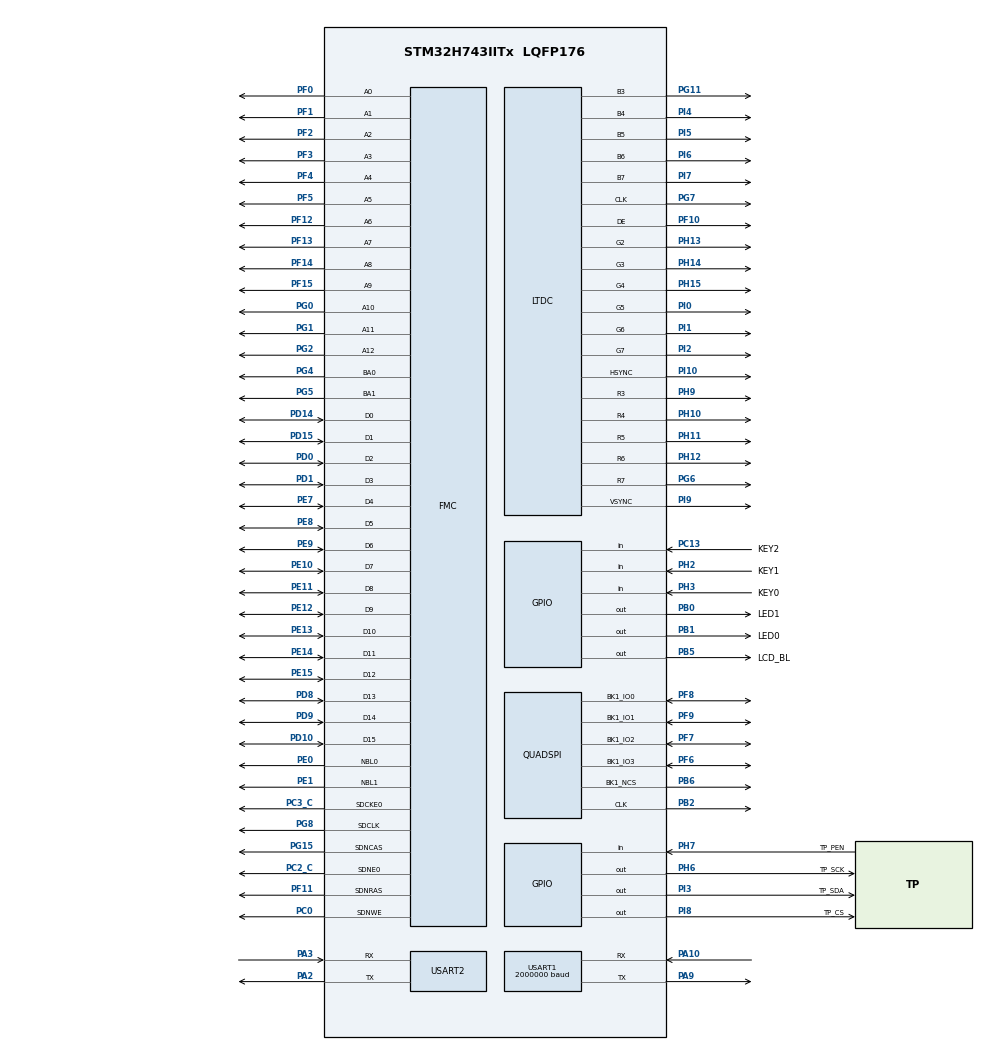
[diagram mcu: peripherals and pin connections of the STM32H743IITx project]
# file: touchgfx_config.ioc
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DMA2D.ColorMode=DMA2D_OUTPUT_RGB565
FMC.CASLatency1=FMC_SDRAM_CAS_LATENCY_3
FMC.ColumnBitsNumber1=FMC_SDRAM_COLUMN_BITS_NUM_9
FMC.ExitSelfRefreshDelay1=8
FMC.LoadToActiveDelay1=2
FMC.RCDDelay1=2
FMC.RPDelay1=2
FMC.RPDelay2=2
FMC.ReadBurst1=FMC_SDRAM_RBURST_ENABLE
FMC.ReadBurst2=FMC_SDRAM_RBURST_ENABLE
FMC.ReadPipeDelay1=FMC_SDRAM_RPIPE_DELAY_1
FMC.ReadPipeDelay2=FMC_SDRAM_RPIPE_DELAY_1
FMC.RowCycleDelay1=6
FMC.RowCycleDelay2=6
FMC.SDClockPeriod1=FMC_SDRAM_CLOCK_PERIOD_2
FMC.SDClockPeriod2=FMC_SDRAM_CLOCK_PERIOD_2
FMC.SelfRefreshTime1=6
FMC.WriteRecoveryTime1=6
FREERTOS.Tasks01=defaultTask,0,128,StartDefaultTask,Default,NULL,Dynamic,NULL,NULL;touchgfx,-2,4096,touchgfx_task,Default,NULL,Dynamic,NULL,NULL
FREERTOS.configTOTAL_HEAP_SIZE=32768
FREERTOS.configUSE_NEWLIB_REENTRANT=1
LTDC.ActiveH=600
LTDC.ActiveW=1024
LTDC.Alpha_L0=255
LTDC.FBStartAdress_L0=0xC0000000
LTDC.HBP=140
LTDC.HFP=160
LTDC.HSync=20
LTDC.ImageHeight_L0=600
LTDC.ImageWidth_L0=1024
LTDC.Layers=0
LTDC.PixelFormat_L0=LTDC_PIXEL_FORMAT_RGB565
LTDC.VBP=20
LTDC.VFP=12
LTDC.VSync=3
LTDC.WindowX1_L0=1024
LTDC.WindowY1_L0=600
Mcu.Family=STM32H7
Mcu.Name=STM32H743IITx
Mcu.Package=LQFP176
NVIC.DMA2D_IRQn=true\:5\:0\:false\:false\:true\:true\:true\:true\:true
NVIC.LTDC_IRQn=true\:8\:0\:true\:false\:true\:true\:true\:true\:true
NVIC.PriorityGroup=NVIC_PRIORITYGROUP_4
NVIC.TIM3_IRQn=true\:7\:0\:true\:false\:true\:true\:true\:true\:true
NVIC.TIM7_IRQn=true\:15\:0\:false\:false\:true\:false\:false\:true\:true
NVIC.TimeBase=TIM7_IRQn
NVIC.TimeBaseIP=TIM7
NVIC.USART1_IRQn=true\:6\:0\:true\:false\:true\:true\:true\:true\:true
NVIC.USART2_IRQn=true\:5\:0\:false\:false\:true\:true\:true\:true\:true
PA10.Mode=Asynchronous
PA10.Signal=USART1_RX
PA13\ (JTMS/SWDIO).Mode=Serial_Wire
PA13\ (JTMS/SWDIO).Signal=DEBUG_JTMS-SWDIO
PA14\ (JTCK/SWCLK).Mode=Serial_Wire
PA14\ (JTCK/SWCLK).Signal=DEBUG_JTCK-SWCLK
PA2.Mode=Asynchronous
PA2.Signal=USART2_TX
PA3.Mode=Asynchronous
PA3.Signal=USART2_RX
PA9.Mode=Asynchronous
PA9.Signal=USART1_TX
PB0.GPIO_Label=LED1
PB0.GPIO_PuPd=GPIO_PULLUP
PB0.GPIO_Speed=GPIO_SPEED_FREQ_HIGH
PB0.PinState=GPIO_PIN_SET
PB0.Signal=GPIO_Output
PB1.GPIO_Label=LED0
PB1.GPIO_PuPd=GPIO_PULLUP
PB1.GPIO_Speed=GPIO_SPEED_FREQ_HIGH
PB1.PinState=GPIO_PIN_SET
PB1.Signal=GPIO_Output
PB2.GPIO_Speed=GPIO_SPEED_FREQ_VERY_HIGH
PB2.Mode=Single Bank 1
PB2.Signal=QUADSPI_CLK
PB5.GPIO_Label=LCD_BL
PB5.PinState=GPIO_PIN_SET
PB5.Signal=GPIO_Output
PB6.GPIO_PuPd=GPIO_PULLUP
PB6.GPIO_Speed=GPIO_SPEED_FREQ_VERY_HIGH
PB6.Mode=Single Bank 1
PB6.Signal=QUADSPI_BK1_NCS
PC0.Signal=FMC_SDNWE
PC13.GPIO_Label=KEY2
PC13.GPIO_PuPd=GPIO_PULLUP
PC13.Signal=GPIO_Input
PC14-OSC32_IN\ (OSC32_IN).Mode=LSE-External-Oscillator
PC14-OSC32_IN\ (OSC32_IN).Signal=RCC_OSC32_IN
PC15-OSC32_OUT\ (OSC32_OUT).Mode=LSE-External-Oscillator
PC15-OSC32_OUT\ (OSC32_OUT).Signal=RCC_OSC32_OUT
PC2_C.Mode=SdramChipSelect1_1
PC2_C.Signal=FMC_SDNE0
PC3_C.Mode=SdramChipSelect1_1
PC3_C.Signal=FMC_SDCKE0
PD0.Signal=FMC_D2_DA2
PD1.Signal=FMC_D3_DA3
PD10.Signal=FMC_D15_DA15
PD14.Signal=FMC_D0_DA0
PD15.Signal=FMC_D1_DA1
PD8.Signal=FMC_D13_DA13
PD9.Signal=FMC_D14_DA14
PE0.Signal=FMC_NBL0
PE1.Signal=FMC_NBL1
PE10.Signal=FMC_D7_DA7
PE11.Signal=FMC_D8_DA8
PE12.Signal=FMC_D9_DA9
PE13.Signal=FMC_D10_DA10
PE14.Signal=FMC_D11_DA11
PE15.Signal=FMC_D12_DA12
PE7.Signal=FMC_D4_DA4
PE8.Signal=FMC_D5_DA5
PE9.Signal=FMC_D6_DA6
PF0.Signal=FMC_A0
PF1.Signal=FMC_A1
PF10.GPIO_Speed=GPIO_SPEED_FREQ_VERY_HIGH
PF10.Mode=RGB565
PF10.Signal=LTDC_DE
PF11.Signal=FMC_SDNRAS
PF12.Signal=FMC_A6
PF13.Signal=FMC_A7
PF14.Signal=FMC_A8
PF15.Signal=FMC_A9
PF2.Signal=FMC_A2
PF3.Signal=FMC_A3
PF4.Signal=FMC_A4
PF5.Signal=FMC_A5
PF6.GPIO_Speed=GPIO_SPEED_FREQ_VERY_HIGH
PF6.Mode=Single Bank 1
PF6.Signal=QUADSPI_BK1_IO3
PF7.GPIO_Speed=GPIO_SPEED_FREQ_VERY_HIGH
PF7.Mode=Single Bank 1
PF7.Signal=QUADSPI_BK1_IO2
PF8.GPIO_Speed=GPIO_SPEED_FREQ_VERY_HIGH
PF8.Mode=Single Bank 1
PF8.Signal=QUADSPI_BK1_IO0
PF9.GPIO_Speed=GPIO_SPEED_FREQ_VERY_HIGH
PF9.Mode=Single Bank 1
PF9.Signal=QUADSPI_BK1_IO1
PG0.Signal=FMC_A10
PG1.Signal=FMC_A11
PG11.GPIO_Speed=GPIO_SPEED_FREQ_VERY_HIGH
PG11.Mode=RGB565
PG11.Signal=LTDC_B3
PG15.Signal=FMC_SDNCAS
PG2.Signal=FMC_A12
PG4.Signal=FMC_A14_BA0
PG5.Signal=FMC_A15_BA1
PG6.GPIO_Speed=GPIO_SPEED_FREQ_VERY_HIGH
PG6.Mode=RGB565
PG6.Signal=LTDC_R7
PG7.GPIO_Speed=GPIO_SPEED_FREQ_VERY_HIGH
PG7.Mode=RGB565
PG7.Signal=LTDC_CLK
PG8.Signal=FMC_SDCLK
PH0-OSC_IN\ (PH0).Mode=HSE-External-Oscillator
PH0-OSC_IN\ (PH0).Signal=RCC_OSC_IN
PH1-OSC_OUT\ (PH1).Mode=HSE-External-Oscillator
PH1-OSC_OUT\ (PH1).Signal=RCC_OSC_OUT
PH10.GPIO_Speed=GPIO_SPEED_FREQ_VERY_HIGH
PH10.Mode=RGB565
PH10.Signal=LTDC_R4
PH11.GPIO_Speed=GPIO_SPEED_FREQ_VERY_HIGH
PH11.Mode=RGB565
PH11.Signal=LTDC_R5
PH12.GPIO_Speed=GPIO_SPEED_FREQ_VERY_HIGH
PH12.Mode=RGB565
PH12.Signal=LTDC_R6
PH13.GPIO_Speed=GPIO_SPEED_FREQ_VERY_HIGH
PH13.Mode=RGB565
PH13.Signal=LTDC_G2
PH14.GPIO_Speed=GPIO_SPEED_FREQ_VERY_HIGH
PH14.Mode=RGB565
PH14.Signal=LTDC_G3
PH15.GPIO_Speed=GPIO_SPEED_FREQ_VERY_HIGH
PH15.Mode=RGB565
PH15.Signal=LTDC_G4
PH2.GPIO_Label=KEY1
PH2.GPIO_PuPd=GPIO_PULLUP
PH2.Signal=GPIO_Input
PH3.GPIO_Label=KEY0
PH3.GPIO_PuPd=GPIO_PULLUP
PH3.Signal=GPIO_Input
PH6.GPIO_Label=TP_SCK
PH6.GPIO_PuPd=GPIO_PULLUP
PH6.GPIO_Speed=GPIO_SPEED_FREQ_HIGH
PH6.PinState=GPIO_PIN_SET
PH6.Signal=GPIO_Output
PH7.GPIO_Label=TP_PEN
PH7.Signal=GPIO_Input
PH9.GPIO_Speed=GPIO_SPEED_FREQ_VERY_HIGH
PH9.Mode=RGB565
PH9.Signal=LTDC_R3
PI0.GPIO_Speed=GPIO_SPEED_FREQ_VERY_HIGH
PI0.Mode=RGB565
PI0.Signal=LTDC_G5
PI1.GPIO_Speed=GPIO_SPEED_FREQ_VERY_HIGH
PI1.Mode=RGB565
PI1.Signal=LTDC_G6
PI10.GPIO_Speed=GPIO_SPEED_FREQ_VERY_HIGH
PI10.Mode=RGB565
PI10.Signal=LTDC_HSYNC
PI2.GPIO_Speed=GPIO_SPEED_FREQ_VERY_HIGH
PI2.Mode=RGB565
PI2.Signal=LTDC_G7
PI3.GPIO_Label=TP_SDA
PI3.GPIO_ModeDefaultOutputPP=GPIO_MODE_OUTPUT_OD
PI3.GPIO_PuPd=GPIO_PULLUP
PI3.PinState=GPIO_PIN_SET
PI3.Signal=GPIO_Output
PI4.GPIO_Speed=GPIO_SPEED_FREQ_VERY_HIGH
PI4.Mode=RGB565
PI4.Signal=LTDC_B4
PI5.GPIO_Speed=GPIO_SPEED_FREQ_VERY_HIGH
PI5.Mode=RGB565
PI5.Signal=LTDC_B5
PI6.GPIO_Speed=GPIO_SPEED_FREQ_VERY_HIGH
PI6.Mode=RGB565
PI6.Signal=LTDC_B6
PI7.GPIO_Speed=GPIO_SPEED_FREQ_VERY_HIGH
PI7.Mode=RGB565
PI7.Signal=LTDC_B7
PI8.GPIO_Label=TP_CS
PI8.GPIO_PuPd=GPIO_PULLUP
PI8.GPIO_Speed=GPIO_SPEED_FREQ_LOW
PI8.PinState=GPIO_PIN_SET
PI8.Signal=GPIO_Output
PI9.GPIO_Speed=GPIO_SPEED_FREQ_VERY_HIGH
PI9.Mode=RGB565
PI9.Signal=LTDC_VSYNC
ProjectManager.HeapSize=0x200
ProjectManager.StackSize=0x400
ProjectManager.TargetToolchain=STM32CubeIDE
QUADSPI.ChipSelectHighTime=QSPI_CS_HIGH_TIME_5_CYCLE
QUADSPI.ClockMode=QSPI_CLOCK_MODE_0
QUADSPI.ClockPrescaler=1
QUADSPI.FifoThreshold=4
QUADSPI.FlashSize=24
QUADSPI.SampleShifting=QSPI_SAMPLE_SHIFTING_HALFCYCLE
RCC.ADCFreq_Value=50390625
RCC.APB1Freq_Value=100000000
RCC.APB2Freq_Value=100000000
RCC.APB3Freq_Value=100000000
RCC.APB4Freq_Value=100000000
RCC.CortexFreq_Value=400000000
RCC.D1PPRE=RCC_APB3_DIV2
RCC.D2PPRE1=RCC_APB1_DIV2
RCC.D2PPRE2=RCC_APB2_DIV2
RCC.D3PPRE=RCC_APB4_DIV2
RCC.DIVM1=2
RCC.DIVN1=64
RCC.DIVN3=192
RCC.DIVR3=3
RCC.HCLKFreq_Value=200000000
RCC.HPRE=RCC_HCLK_DIV2
RCC.PLL2FRACN=0
RCC.PLL3FRACN=0
RCC.PLLFRACN=0
RCC.PLLSourceVirtual=RCC_PLLSOURCE_HSE
RCC.SYSCLKFreq_VALUE=400000000
RCC.SYSCLKSource=RCC_SYSCLKSOURCE_PLLCLK
RCC.USBFreq_Value=400000000
SH.FMC_A0.0=FMC_A0,13b-sda1
SH.FMC_A1.0=FMC_A1,13b-sda1
SH.FMC_A10.0=FMC_A10,13b-sda1
SH.FMC_A11.0=FMC_A11,13b-sda1
SH.FMC_A12.0=FMC_A12,13b-sda1
SH.FMC_A14_BA0.0=FMC_BA0,FourSdramBanks1
SH.FMC_A15_BA1.0=FMC_BA1,FourSdramBanks1
SH.FMC_A2.0=FMC_A2,13b-sda1
SH.FMC_A3.0=FMC_A3,13b-sda1
SH.FMC_A4.0=FMC_A4,13b-sda1
SH.FMC_A5.0=FMC_A5,13b-sda1
SH.FMC_A6.0=FMC_A6,13b-sda1
SH.FMC_A7.0=FMC_A7,13b-sda1
SH.FMC_A8.0=FMC_A8,13b-sda1
SH.FMC_A9.0=FMC_A9,13b-sda1
SH.FMC_D0_DA0.0=FMC_D0,sd-16b-d1
SH.FMC_D10_DA10.0=FMC_D10,sd-16b-d1
SH.FMC_D11_DA11.0=FMC_D11,sd-16b-d1
SH.FMC_D12_DA12.0=FMC_D12,sd-16b-d1
SH.FMC_D13_DA13.0=FMC_D13,sd-16b-d1
SH.FMC_D14_DA14.0=FMC_D14,sd-16b-d1
SH.FMC_D15_DA15.0=FMC_D15,sd-16b-d1
SH.FMC_D1_DA1.0=FMC_D1,sd-16b-d1
SH.FMC_D2_DA2.0=FMC_D2,sd-16b-d1
SH.FMC_D3_DA3.0=FMC_D3,sd-16b-d1
SH.FMC_D4_DA4.0=FMC_D4,sd-16b-d1
SH.FMC_D5_DA5.0=FMC_D5,sd-16b-d1
SH.FMC_D6_DA6.0=FMC_D6,sd-16b-d1
SH.FMC_D7_DA7.0=FMC_D7,sd-16b-d1
SH.FMC_D8_DA8.0=FMC_D8,sd-16b-d1
SH.FMC_D9_DA9.0=FMC_D9,sd-16b-d1
SH.FMC_NBL0.0=FMC_NBL0,Sd2ByteEnable1
SH.FMC_NBL1.0=FMC_NBL1,Sd2ByteEnable1
SH.FMC_SDCLK.0=FMC_SDCLK,13b-sda1
SH.FMC_SDNCAS.0=FMC_SDNCAS,13b-sda1
SH.FMC_SDNRAS.0=FMC_SDNRAS,13b-sda1
SH.FMC_SDNWE.0=FMC_SDNWE,13b-sda1
STMicroelectronics.X-CUBE-TOUCHGFX.4.22.1.ApplicationCcGraphicsJjApplication=TouchGFXOoGenerator
STMicroelectronics.X-CUBE-TOUCHGFX.4.22.1.tgfx_address1=0xC0000000
STMicroelectronics.X-CUBE-TOUCHGFX.4.22.1.tgfx_custom_height=600
STMicroelectronics.X-CUBE-TOUCHGFX.4.22.1.tgfx_display_interface=disp_ltdc
STMicroelectronics.X-CUBE-TOUCHGFX.4.22.1.tgfx_hardware_accelerator=dma_2d
STMicroelectronics.X-CUBE-TOUCHGFX.4.22.1.tgfx_location=By Address
STMicroelectronics.X-CUBE-TOUCHGFX.4.22.1.tgfx_vsync=vsync_ltdc
STMicroelectronics.X-CUBE-TOUCHGFX.4.22.1_IsPackSelfContextualization=true
USART1.BaudRate=2000000
USART1.VirtualMode-Asynchronous=VM_ASYNC
USART2.VirtualMode-Asynchronous=VM_ASYNC
VP_CRC_VS_CRC.Mode=CRC_Activate
VP_DMA2D_VS_DMA2D.Mode=DMA2D_Activate
VP_FREERTOS_VS_CMSIS_V1.Mode=CMSIS_V1
VP_STMicroelectronics.X-CUBE-TOUCHGFX_VS_GraphicsJjApplication_4.22.1.Mode=GraphicsJjApplication
VP_SYS_VS_tim7.Mode=TIM7
VP_TIM3_VS_ClockSourceINT.Mode=Internal
board=custom

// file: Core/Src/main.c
/* USER CODE BEGIN Header */
/**
  ******************************************************************************
  * @file           : main.c
  * @brief          : Main program body
  ******************************************************************************
  * @attention
  *
  * Copyright (c) 2023 STMicroelectronics.
  * All rights reserved.
  *
  * This software is licensed under terms that can be found in the LICENSE file
  * in the root directory of this software component.
  * If no LICENSE file comes with this software, it is provided AS-IS.
  *
  ******************************************************************************
  */
/* USER CODE END Header */
#include "main.h"
#include "cmsis_os.h"
#include "crc.h"
#include "dma2d.h"
#include "ltdc.h"
#include "quadspi.h"
#include "tim.h"
#include "usart.h"
#include "gpio.h"
#include "fmc.h"
#include "app_touchgfx.h"

/* USER CODE BEGIN Includes */
#include "sdram.h"
#include "stdio.h"
#include "user_uart.h"
#include "key_led.h"
#include "user_delay.h"
#include "touch.h"
#include "quadspi.h"

/* USER CODE END Includes */

void SystemClock_Config(void);
void MX_FREERTOS_Init(void);

int main(void)
{

  /* MCU Configuration--------------------------------------------------------*/

  /* Reset of all peripherals, Initializes the Flash interface and the Systick. */
  HAL_Init();

  /* Configure the system clock */
  SystemClock_Config();

  /* Initialize all configured peripherals */
  MX_GPIO_Init();
  MX_TIM3_Init();
  MX_USART1_UART_Init();
  MX_USART2_UART_Init();
  MX_FMC_Init();
  MX_LTDC_Init();
  MX_DMA2D_Init();
  MX_QUADSPI_Init();
  MX_CRC_Init();
  MX_TouchGFX_Init();
  /* Call PreOsInit function */
  MX_TouchGFX_PreOSInit();
  /* USER CODE BEGIN 2 */
  log_com_uart_init();
  SDRAM_Init();
  w25qxx_flash_init();
  /* USER CODE END 2 */

  /* Call init function for freertos objects (in freertos.c) */
  MX_FREERTOS_Init();

  /* Start scheduler */
  osKernelStart();

  /* We should never get here as control is now taken by the scheduler */
  /* Infinite loop */
  while (1)
  {

  }
}

void SystemClock_Config(void)
{
  RCC_OscInitTypeDef RCC_OscInitStruct = {0};
  RCC_ClkInitTypeDef RCC_ClkInitStruct = {0};

  /** Supply configuration update enable
  */
  HAL_PWREx_ConfigSupply(PWR_LDO_SUPPLY);

  /** Configure the main internal regulator output voltage
  */
  __HAL_PWR_VOLTAGESCALING_CONFIG(PWR_REGULATOR_VOLTAGE_SCALE1);

  while(!__HAL_PWR_GET_FLAG(PWR_FLAG_VOSRDY)) {}

  /** Initializes the RCC Oscillators according to the specified parameters
  * in the RCC_OscInitTypeDef structure.
  */
  RCC_OscInitStruct.OscillatorType = RCC_OSCILLATORTYPE_HSE;
  RCC_OscInitStruct.HSEState = RCC_HSE_ON;
  RCC_OscInitStruct.PLL.PLLState = RCC_PLL_ON;
  RCC_OscInitStruct.PLL.PLLSource = RCC_PLLSOURCE_HSE;
  RCC_OscInitStruct.PLL.PLLM = 2;
  RCC_OscInitStruct.PLL.PLLN = 64;
  RCC_OscInitStruct.PLL.PLLP = 2;
  RCC_OscInitStruct.PLL.PLLQ = 2;
  RCC_OscInitStruct.PLL.PLLR = 2;
  RCC_OscInitStruct.PLL.PLLRGE = RCC_PLL1VCIRANGE_3;
  RCC_OscInitStruct.PLL.PLLVCOSEL = RCC_PLL1VCOWIDE;
  RCC_OscInitStruct.PLL.PLLFRACN = 0;
  if (HAL_RCC_OscConfig(&RCC_OscInitStruct) != HAL_OK)
  {
    Error_Handler();
  }

  /** Initializes the CPU, AHB and APB buses clocks
  */
  RCC_ClkInitStruct.ClockType = RCC_CLOCKTYPE_HCLK|RCC_CLOCKTYPE_SYSCLK
                              |RCC_CLOCKTYPE_PCLK1|RCC_CLOCKTYPE_PCLK2
                              |RCC_CLOCKTYPE_D3PCLK1|RCC_CLOCKTYPE_D1PCLK1;
  RCC_ClkInitStruct.SYSCLKSource = RCC_SYSCLKSOURCE_PLLCLK;
  RCC_ClkInitStruct.SYSCLKDivider = RCC_SYSCLK_DIV1;
  RCC_ClkInitStruct.AHBCLKDivider = RCC_HCLK_DIV2;
  RCC_ClkInitStruct.APB3CLKDivider = RCC_APB3_DIV2;
  RCC_ClkInitStruct.APB1CLKDivider = RCC_APB1_DIV2;
  RCC_ClkInitStruct.APB2CLKDivider = RCC_APB2_DIV2;
  RCC_ClkInitStruct.APB4CLKDivider = RCC_APB4_DIV2;

  if (HAL_RCC_ClockConfig(&RCC_ClkInitStruct, FLASH_LATENCY_2) != HAL_OK)
  {
    Error_Handler();
  }
}

void HAL_TIM_PeriodElapsedCallback(TIM_HandleTypeDef *htim)
{
  if (htim->Instance == TIM7) {
    HAL_IncTick();
  }
}

void Error_Handler(void)
{
  __disable_irq();
  while (1)
  {
  }
}

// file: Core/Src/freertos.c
/* USER CODE BEGIN Header */
/**
  ******************************************************************************
  * File Name          : freertos.c
  * Description        : Code for freertos applications
  ******************************************************************************
  * @attention
  *
  * Copyright (c) 2023 STMicroelectronics.
  * All rights reserved.
  *
  * This software is licensed under terms that can be found in the LICENSE file
  * in the root directory of this software component.
  * If no LICENSE file comes with this software, it is provided AS-IS.
  *
  ******************************************************************************
  */
/* USER CODE END Header */

#include "FreeRTOS.h"
#include "task.h"
#include "main.h"
#include "cmsis_os.h"

/* USER CODE BEGIN Includes */
#include "app_touchgfx.h"
/* USER CODE END Includes */

osThreadId defaultTaskHandle;
osThreadId touchgfxHandle;

void StartDefaultTask(void const * argument);
void touchgfx_task(void const * argument);

void MX_FREERTOS_Init(void); /* (MISRA C 2004 rule 8.1) */

/* GetIdleTaskMemory prototype (linked to static allocation support) */
void vApplicationGetIdleTaskMemory( StaticTask_t **ppxIdleTaskTCBBuffer, StackType_t **ppxIdleTaskStackBuffer, uint32_t *pulIdleTaskStackSize );

/* USER CODE BEGIN GET_IDLE_TASK_MEMORY */
static StaticTask_t xIdleTaskTCBBuffer;
static StackType_t xIdleStack[configMINIMAL_STACK_SIZE];

void vApplicationGetIdleTaskMemory( StaticTask_t **ppxIdleTaskTCBBuffer, StackType_t **ppxIdleTaskStackBuffer, uint32_t *pulIdleTaskStackSize )
{
  *ppxIdleTaskTCBBuffer = &xIdleTaskTCBBuffer;
  *ppxIdleTaskStackBuffer = &xIdleStack[0];
  *pulIdleTaskStackSize = configMINIMAL_STACK_SIZE;
  /* place for user code */
}
/* USER CODE END GET_IDLE_TASK_MEMORY */

void MX_FREERTOS_Init(void) {

  /* Create the thread(s) */
  /* definition and creation of defaultTask */
  osThreadDef(defaultTask, StartDefaultTask, osPriorityNormal, 0, 128);
  defaultTaskHandle = osThreadCreate(osThread(defaultTask), NULL);

  /* definition and creation of touchgfx */
  osThreadDef(touchgfx, touchgfx_task, osPriorityLow, 0, 4096);
  touchgfxHandle = osThreadCreate(osThread(touchgfx), NULL);

}

void StartDefaultTask(void const * argument)
{
  /* USER CODE BEGIN StartDefaultTask */
  /* Infinite loop */
  for(;;)
  {
//	HAL_Delay(1);
	HAL_GPIO_TogglePin(LED0_GPIO_Port, LED0_Pin);
	HAL_GPIO_TogglePin(LED1_GPIO_Port, LED1_Pin);
	printf(" StartDefaultTask run \n");
    osDelay(500);
  }
  /* USER CODE END StartDefaultTask */
}

void touchgfx_task(void const * argument)
{
  /* USER CODE BEGIN touchgfx_task */

  /* Infinite loop */
  for(;;)
  {
	MX_TouchGFX_Process();
    osDelay(1);
  }
  /* USER CODE END touchgfx_task */
}
